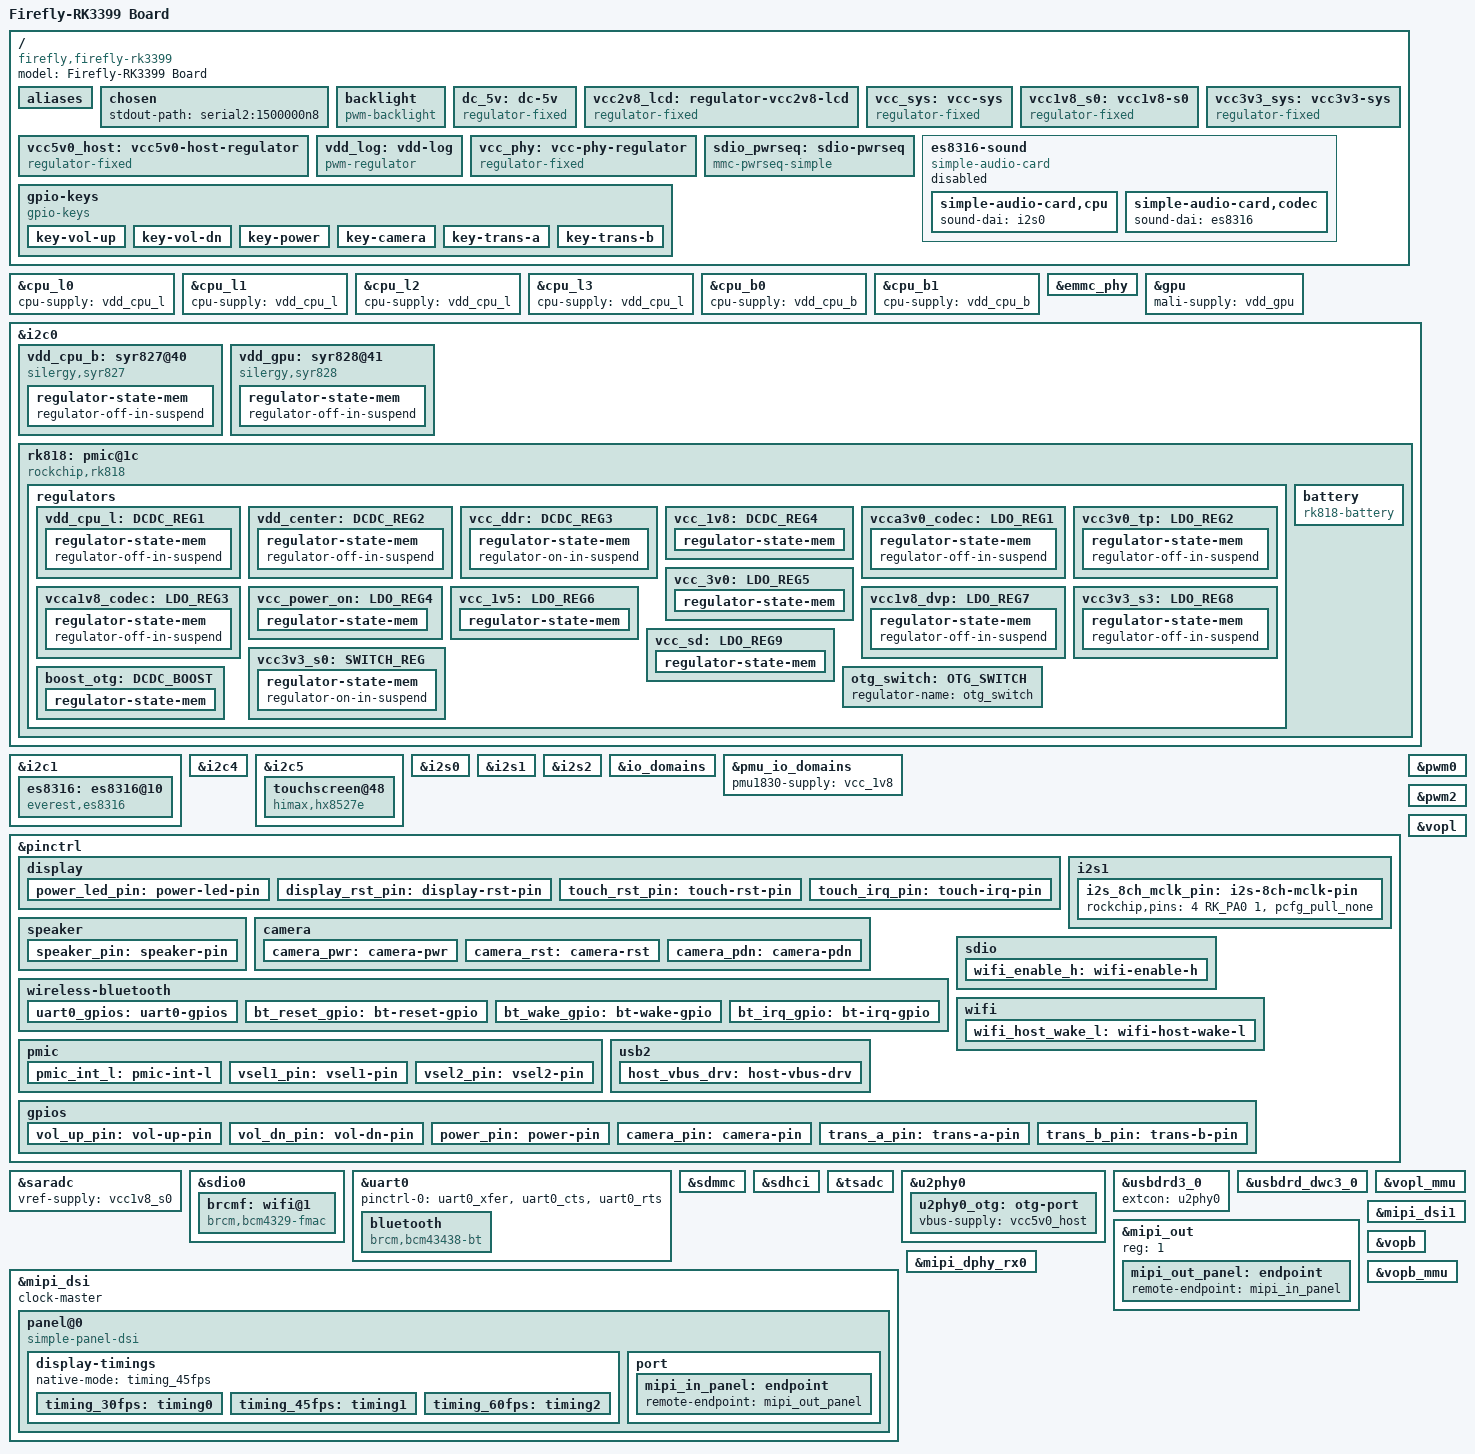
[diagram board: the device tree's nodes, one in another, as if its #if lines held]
// SPDX-License-Identifier: (GPL-2.0+ OR MIT)
/*
 * Copyright (c) 2017 Fuzhou Rockchip Electronics Co., Ltd.
 */

/dts-v1/;
#include <dt-bindings/input/linux-event-codes.h>
#include <dt-bindings/interrupt-controller/irq.h>
#include <dt-bindings/pwm/pwm.h>
#include <dt-bindings/usb/pd.h>
#include "rk3399.dtsi"

#define BLUETOOTH_ON  1
#define GPU_STRATEGY  0 /*1:Panfrost GPU  0:Midgard GPU*/
#define CAMERA_ONLINE 0
#define MAINLINE_LINUX	  1
/ {
	model = "Firefly-RK3399 Board";
	compatible = "firefly,firefly-rk3399", "rockchip,rk3399";

	aliases {
		mmc2 = &sdio0;
		mmc1 = &sdmmc;
		mmc0 = &sdhci;
	};

	chosen {
		stdout-path = "serial2:1500000n8";
	};

	//DONE 
	backlight: backlight {
		compatible = "pwm-backlight";
		enable-gpios = <&gpio1 RK_PB5 GPIO_ACTIVE_HIGH>;
		pwms = <&pwm0 0 25000 0>;
		brightness-levels = <
			  0   1   2   3   4   5   6   7
			  8   9  10  11  12  13  14  15
			 16  17  18  19  20  21  22  23
			 24  25  26  27  28  29  30  31
			 32  33  34  35  36  37  38  39
			 40  41  42  43  44  45  46  47
			 48  49  50  51  52  53  54  55
			 56  57  58  59  60  61  62  63
			 64  65  66  67  68  69  70  71
			 72  73  74  75  76  77  78  79
			 80  81  82  83  84  85  86  87
			 88  89  90  91  92  93  94  95
			 96  97  98  99 100 101 102 103
			104 105 106 107 108 109 110 111
			112 113 114 115 116 117 118 119
			120 121 122 123 124 125 126 127
			128 129 130 131 132 133 134 135
			136 137 138 139 140 141 142 143
			144 145 146 147 148 149 150 151
			152 153 154 155 156 157 158 159
			160 161 162 163 164 165 166 167
			168 169 170 171 172 173 174 175
			176 177 178 179 180 181 182 183
			184 185 186 187 188 189 190 191
			192 193 194 195 196 197 198 199
			200 201 202 203 204 205 206 207
			208 209 210 211 212 213 214 215
			216 217 218 219 220 221 222 223
			224 225 226 227 228 229 230 231
			232 233 234 235 236 237 238 239
			240 241 242 243 244 245 246 247
			248 249 250 251 252 253 254 255>;
		default-brightness-level = <250>;
	};

	dc_5v: dc-5v {
		compatible = "regulator-fixed";
		regulator-name = "dc_5v";
		regulator-always-on;
		regulator-boot-on;
		regulator-min-microvolt = <5000000>;
		regulator-max-microvolt = <5000000>;
	};

    vcc2v8_lcd: regulator-vcc2v8-lcd {
        compatible = "regulator-fixed";
        regulator-name = "vcc2v8_lcd";
		regulator-always-on;
		regulator-boot-on;
        regulator-min-microvolt = <2800000>;
        regulator-max-microvolt = <2800000>;
        vin-supply = <&dc_5v>;
    };


	//DONE
	vcc_sys: vcc-sys {
		compatible = "regulator-fixed";
		regulator-name = "vcc_sys";
		regulator-min-microvolt = <5000000>;
		regulator-max-microvolt = <5000000>;
		regulator-always-on;
		vin-supply = <&dc_5v>;
	};

	vcc1v8_s0: vcc1v8-s0 {
		compatible = "regulator-fixed";
		regulator-name = "vcc1v8_s0";
		regulator-min-microvolt = <1800000>;
		regulator-max-microvolt = <1800000>;
		regulator-always-on;
	};

	//DONE
	vcc3v3_sys: vcc3v3-sys {
		compatible = "regulator-fixed";
		regulator-name = "vcc3v3_sys";
		regulator-min-microvolt = <3300000>;
		regulator-max-microvolt = <3300000>;
		regulator-always-on;
		regulator-boot-on;
		vin-supply = <&vcc_sys>;
	};

	//DONE
#if (BAT_ALWAYS_CHARGE == 0)
	vcc5v0_host: vcc5v0-host-regulator {
		compatible = "regulator-fixed";
		enable-active-high;
		gpio = <&gpio4 RK_PD1 GPIO_ACTIVE_HIGH>;
		pinctrl-names = "default";
		pinctrl-0 = <&host_vbus_drv>;
		regulator-name = "vcc5v0_host";
		regulator-always-on;
	};
#endif 

	//DONE
	vdd_log: vdd-log {
		compatible = "pwm-regulator";
		pwms = <&pwm2 0 25000 1>;
		pwm-supply = <&vcc_sys>;
		regulator-name = "vdd_log";
		regulator-min-microvolt = <750000>;
		regulator-max-microvolt = <1350000>;
		regulator-always-on;
		regulator-boot-on;
	};

	//DONE
	vcc_phy: vcc-phy-regulator {
		compatible = "regulator-fixed";
		regulator-name = "vcc_phy";
		regulator-always-on;
		regulator-boot-on;
	};


	//DONE
	sdio_pwrseq: sdio-pwrseq {
		compatible = "mmc-pwrseq-simple";
		clocks = <&rk818 1>;
		clock-names = "ext_clock";
		pinctrl-names = "default";
		pinctrl-0 = <&wifi_enable_h>;
		reset-gpios = <&gpio0 RK_PB2 GPIO_ACTIVE_LOW>;
	};

	//DONE 
	gpio-keys {
		compatible = "gpio-keys";
		#address-cells = <1>;
		#size-cells = <0>;
		autorepeat;
		pinctrl-names = "default";
		pinctrl-0 = <&vol_up_pin>,<&vol_dn_pin>,<&power_pin>,<&camera_pin>,<&trans_a_pin>,<&trans_b_pin>;

		key-vol-up {
			debounce-interval = <100>;
			gpios = <&gpio1 RK_PB2 GPIO_ACTIVE_LOW>;
			label = "GPIO Key V+";
			linux,code = <KEY_VOLUMEUP>;
		};

		key-vol-dn {
			debounce-interval = <100>;
			gpios = <&gpio1 RK_PB0 GPIO_ACTIVE_LOW>;
			label = "GPIO Key V-";
			linux,code = <KEY_VOLUMEDOWN>;
		};

		key-power {
			debounce-interval = <100>;
			gpios = <&gpio0 RK_PA5 GPIO_ACTIVE_LOW>;
			label = "GPIO Key Power";
			linux,code = <KEY_POWER>;
		};

		key-camera {
			debounce-interval = <100>;
			gpios = <&gpio1 RK_PA1 GPIO_ACTIVE_LOW>;
			label = "GPIO key camera";
			linux,code = <KEY_ENTER>;
		};

		key-trans-a {
			debounce-interval = <100>;
			gpios = <&gpio1 RK_PC7 GPIO_ACTIVE_LOW>;
			label = "GPIO key trans a";
			linux,code = <KEY_UP>;
		};

		key-trans-b {
			debounce-interval = <100>;
			gpios = <&gpio1 RK_PC2 GPIO_ACTIVE_LOW>;
			label = "GPIO Key trans b";
			linux,code = <KEY_DOWN>;
		};
	};

	//DONE
	es8316-sound {
		compatible = "simple-audio-card";
		simple-audio-card,format = "i2s";
		simple-audio-card,name = "rockchip,es8316-codec";
		simple-audio-card,mclk-fs = <256>;

		status = "disabled";

		simple-audio-card,widgets =
			"Microphone", "Mic1 Jack",
			"Microphone", "Mic2 Jack",
			"Headphone", "Headphone Jack";

		simple-audio-card,routing =
			"Mic1 Jack", "Mic Bias",
			"MIC1", "Mic1 Jack",
			"Mic2 Jack", "Mic Bias",
			"MIC2", "Mic2 Jack",
			"Headphone Jack", "HPOL",
			"Headphone Jack", "HPOR";

		simple-audio-card,cpu {
			sound-dai = <&i2s0>;
		};

		simple-audio-card,codec {
			sound-dai = <&es8316>;
		};
	};
};

&cpu_l0 {
	cpu-supply = <&vdd_cpu_l>;
};

&cpu_l1 {
	cpu-supply = <&vdd_cpu_l>;
};

&cpu_l2 {
	cpu-supply = <&vdd_cpu_l>;
};

&cpu_l3 {
	cpu-supply = <&vdd_cpu_l>;
};

&cpu_b0 {
	cpu-supply = <&vdd_cpu_b>;
};

&cpu_b1 {
	cpu-supply = <&vdd_cpu_b>;
};

&emmc_phy {
	status = "okay";
};


&gpu {
#if GPU_STRATEGY
	compatible = "rockchip,rk3399-mali", "arm,mali-t860";
#endif 
	mali-supply = <&vdd_gpu>;
	status = "okay";
};


&i2c0 {
	status = "okay";
	i2c-scl-rising-time-ns = <180>;
	i2c-scl-falling-time-ns = <30>;
	clock-frequency = <400000>;

	//DONE
	vdd_cpu_b: syr827@40 {
		compatible = "silergy,syr827";
		reg = <0x40>;
		regulator-compatible = "fan53555-reg";
		pinctrl-0 = <&vsel1_pin>;
		vsel-gpios = <&gpio1 RK_PC1 GPIO_ACTIVE_HIGH>;
		regulator-name = "vdd_cpu_b";
		regulator-min-microvolt = <712500>;
		regulator-max-microvolt = <1500000>;
		regulator-ramp-delay = <1000>;
		fcs,suspend-voltage-selector = <1>;
		regulator-always-on;
		regulator-boot-on;
		vin-supply = <&vcc_sys>;
		regulator-state-mem {
			regulator-off-in-suspend;
		};
	};


	//DONE
	vdd_gpu: syr828@41 {
		compatible = "silergy,syr828";
		reg = <0x41>;
		regulator-compatible = "fan53555-reg";
		pinctrl-0 = <&vsel2_pin>;
		vsel-gpios = <&gpio1 RK_PB6 GPIO_ACTIVE_HIGH>;
		regulator-name = "vdd_gpu";
		regulator-min-microvolt = <712500>;
		regulator-max-microvolt = <1500000>;
		regulator-ramp-delay = <1000>;
		fcs,suspend-voltage-selector = <1>;
		regulator-always-on;
		regulator-boot-on;
		vin-supply = <&vcc_sys>;
		regulator-initial-mode = <1>;
		regulator-state-mem {
			regulator-off-in-suspend;
		};
	};

	//DONE
	rk818: pmic@1c {
		compatible = "rockchip,rk818";
		status = "okay";
		reg = <0x1c>;
		clock-output-names = "rk818-clkout1", "wifibt_32kin";
		interrupt-parent = <&gpio1>;
		interrupts = <21 IRQ_TYPE_LEVEL_LOW>;
		pinctrl-names = "default";
		pinctrl-0 = <&pmic_int_l>;
		rockchip,system-power-controller;
		
#if (BAT_ALWAYS_CHARGE == 0)
	rk818,support_dc_chg = <1>;/*1: dc chg; 0:usb chg*/
#else
	rk818,support_dc_chg = <0>;/*1: dc chg; 0:usb chg*/
#endif 
		extcon = <&u2phy0>;
		wakeup-source;
		#clock-cells = <1>;

		vcc1-supply = <&vcc_sys>;
		vcc2-supply = <&vcc_sys>;
		vcc3-supply = <&vcc_sys>;
		vcc4-supply = <&vcc_sys>;
		vcc6-supply = <&vcc_sys>;
		vcc7-supply = <&vcc3v3_sys>;
		vcc8-supply = <&vcc_sys>;
		vcc9-supply = <&vcc3v3_sys>;

		regulators {
			vdd_cpu_l: DCDC_REG1 {
				regulator-name = "vdd_cpu_l";
				regulator-always-on;
				regulator-boot-on;
				regulator-min-microvolt = <750000>;
				regulator-max-microvolt = <1350000>;
				regulator-ramp-delay = <6001>;
				regulator-state-mem {
					regulator-off-in-suspend;
				};
			};

			vdd_center: DCDC_REG2 {
				regulator-name = "vdd_center";
				regulator-always-on;
				regulator-boot-on;
				regulator-min-microvolt = <800000>;
				regulator-max-microvolt = <1350000>;
				regulator-ramp-delay = <6001>;
				regulator-state-mem {
					regulator-off-in-suspend;
				};
			};

			vcc_ddr: DCDC_REG3 {
				regulator-name = "vcc_ddr";
				regulator-always-on;
				regulator-boot-on;
				regulator-state-mem {
					regulator-on-in-suspend;
				};
			};

			vcc_1v8: DCDC_REG4 {
				regulator-name = "vcc_1v8";
				regulator-always-on;
				regulator-boot-on;
				regulator-min-microvolt = <1800000>;
				regulator-max-microvolt = <1800000>;
				regulator-state-mem {
					regulator-on-in-suspend;
					regulator-suspend-microvolt = <1800000>;
				};
			};

			vcca3v0_codec: LDO_REG1 {
				regulator-always-on;
				regulator-boot-on;
				regulator-min-microvolt = <3000000>;
				regulator-max-microvolt = <3000000>;
				regulator-name = "vcca3v0_codec";
				regulator-state-mem {
					regulator-off-in-suspend;
				};
			};

			vcc3v0_tp: LDO_REG2 {
				regulator-always-on;
				regulator-boot-on;
				regulator-min-microvolt = <3000000>;
				regulator-max-microvolt = <3000000>;
				regulator-name = "vcc3v0_tp";
				regulator-state-mem {
					regulator-off-in-suspend;
				};
			};

			vcca1v8_codec: LDO_REG3 {
				regulator-always-on;
				regulator-boot-on;
				regulator-min-microvolt = <1800000>;
				regulator-max-microvolt = <1800000>;
				regulator-name = "vcca1v8_codec";
				regulator-state-mem {
					regulator-off-in-suspend;
				};
			};

			vcc_power_on: LDO_REG4 {
				regulator-always-on;
				regulator-boot-on;
				regulator-min-microvolt = <3300000>;
				regulator-max-microvolt = <3300000>;
				regulator-name = "vcc_power_on";
				regulator-state-mem {
					regulator-on-in-suspend;
					regulator-suspend-microvolt = <3300000>;
				};
			};

			vcc_3v0: LDO_REG5 {
				regulator-always-on;
				regulator-boot-on;
				regulator-min-microvolt = <3000000>;
				regulator-max-microvolt = <3000000>;
				regulator-name = "vcc_3v0";
				regulator-state-mem {
					regulator-on-in-suspend;
					regulator-suspend-microvolt = <3000000>;
				};
			};

			vcc_1v5: LDO_REG6 {
				regulator-always-on;
				regulator-boot-on;
				regulator-min-microvolt = <1500000>;
				regulator-max-microvolt = <1500000>;
				regulator-name = "vcc_1v5";
				regulator-state-mem {
					regulator-on-in-suspend;
					regulator-suspend-microvolt = <1500000>;
				};
			};

			vcc1v8_dvp: LDO_REG7 {
				regulator-always-on;
				regulator-boot-on;
				regulator-min-microvolt = <1800000>;
				regulator-max-microvolt = <1800000>;
				regulator-name = "vcc1v8_dvp";
				regulator-state-mem {
					regulator-off-in-suspend;
				};
			};

			vcc3v3_s3: LDO_REG8 {
				regulator-always-on;
				regulator-boot-on;
				regulator-min-microvolt = <2600000>;
				regulator-max-microvolt = <3300000>;
				regulator-name = "vcc3v3_s3";
				regulator-state-mem {
					regulator-off-in-suspend;
				};
			};

			vcc_sd: LDO_REG9 {
				regulator-always-on;
				regulator-boot-on;
				regulator-min-microvolt = <1800000>;
				regulator-max-microvolt = <3300000>;
				regulator-name = "vcc_sd";
				regulator-state-mem {
					regulator-on-in-suspend;
					regulator-suspend-microvolt = <3300000>;
				};
			};

			vcc3v3_s0: SWITCH_REG {
				regulator-always-on;
				regulator-boot-on;
				regulator-name = "vcc3v3_s0";
				regulator-state-mem {
					regulator-on-in-suspend;
				};
			};

			boost_otg: DCDC_BOOST {
				regulator-name = "boost_otg";
				regulator-always-on;
				regulator-boot-on;
				regulator-min-microvolt = <5000000>;
				regulator-max-microvolt = <5000000>;
				regulator-state-mem {
					regulator-on-in-suspend;
					regulator-suspend-microvolt = <5000000>;
				};
			};

			otg_switch: OTG_SWITCH {
				regulator-name = "otg_switch";
			};
		};

		battery {
			compatible = "rk818-battery";
			ocv_table = <3400 3675 3689 3716 3740 3756 3768 3780
				3793 3807 3827 3853 3896 3937 3974 4007 4066
				4110 4161 4217 4308>;
			design_capacity = <1826>;
			design_qmax = <2009>;
			bat_res = <100>;
			max_input_current = <2000>;
			max_chrg_current = <1800>;
			max_chrg_voltage = <4350>;
			sleep_enter_current = <300>;
			sleep_exit_current = <300>;
			power_off_thresd = <3500>;
			zero_algorithm_vol = <3950>;
			fb_temperature = <105>;
			sample_res = <10>;
			max_soc_offset = <60>;
			energy_mode = <0>;
			monitor_sec = <5>;
			virtual_power = <0>;
			power_dc2otg = <0>;
		};
	};
};



&i2c1 {
	status = "okay";
	clock-frequency = <400000>;
	i2c-scl-rising-time-ns = <300>;
	i2c-scl-falling-time-ns = <30>;

	es8316: es8316@10 {
		#sound-dai-cells = <0>;
		compatible = "everest,es8316";
		reg = <0x10>;
		clocks = <&cru SCLK_I2S_8CH_OUT>;
		clock-names = "mclk";
		pinctrl-names = "default";
		pinctrl-0 = <&i2s_8ch_mclk_pin>, <&speaker_pin>;
		spk-con-gpio = <&gpio4 RK_PD4 GPIO_ACTIVE_HIGH>;
	};
};

&i2c4 {
	clock-frequency = <400000>;
	i2c-scl-rising-time-ns = <600>;
	i2c-scl-falling-time-ns = <40>;
	status = "okay";
};

&i2c5 {
	clock-frequency = <400000>;
	i2c-scl-rising-time-ns = <600>;
	i2c-scl-falling-time-ns = <40>;
	status = "okay";
	touchscreen@48 {
		reg = <0x48>;
		compatible = "himax,hx8527e", "himax,hx852es";
		interrupt-parent = <&gpio3>;
		interrupts = <RK_PB5 IRQ_TYPE_EDGE_FALLING>;
		
		pinctrl-names = "default";
		pinctrl-0 =   <&touch_rst_pin>,<&touch_irq_pin>;
		reset-gpios = <&gpio3 RK_PB4 GPIO_ACTIVE_LOW>;
		vcca-supply = <&vcc3v0_tp>;

		touchscreen-size-x = <480>;
		touchscreen-size-y = <800>;
	};
};

&i2s0 {
	rockchip,i2s-broken-burst-len;
	rockchip,playback-channels = <8>;
	rockchip,capture-channels = <8>;
	#sound-dai-cells = <0>;
	status = "okay";
};


&i2s1 {
	rockchip,playback-channels = <2>;
	rockchip,capture-channels = <2>;
	status = "okay";
};

&i2s2 {
	status = "okay";
};

&io_domains {
	status = "okay";
	bt656-supply = <&vcc1v8_dvp>;
	audio-supply = <&vcca1v8_codec>;
	sdmmc-supply = <&vcc_sd>;
	gpio1830-supply = <&vcc_3v0>;
};


&pmu_io_domains {
	status = "okay";
	pmu1830-supply = <&vcc_1v8>;
};


&pinctrl {
	display {
		power_led_pin: power-led-pin {
			rockchip,pins = <1 RK_PB5 RK_FUNC_GPIO &pcfg_pull_none>;
		};

		display_rst_pin: display-rst-pin {
			rockchip,pins = <3 RK_PA4 RK_FUNC_GPIO &pcfg_pull_none>;
		};

		touch_rst_pin: touch-rst-pin {
			rockchip,pins = <3 RK_PB4 RK_FUNC_GPIO &pcfg_pull_none>;
		};

		touch_irq_pin: touch-irq-pin {
			rockchip,pins = <3 RK_PB5 RK_FUNC_GPIO &pcfg_pull_up>;
		};
	};

	i2s1 {
		i2s_8ch_mclk_pin: i2s-8ch-mclk-pin {
			rockchip,pins = <4 RK_PA0 1 &pcfg_pull_none>;
		};
	};

	speaker {
		speaker_pin: speaker-pin {
			rockchip,pins = <4 RK_PD4 RK_FUNC_GPIO &pcfg_pull_up>;
		};
	};

	camera {
		camera_pwr: camera-pwr {
			rockchip,pins = <1 RK_PA2 RK_FUNC_GPIO &pcfg_pull_up>;
		};

		camera_rst: camera-rst {
			rockchip,pins = <2 RK_PD3 RK_FUNC_GPIO &pcfg_pull_up>;
		};

		camera_pdn: camera-pdn {
			rockchip,pins = <2 RK_PD4 RK_FUNC_GPIO &pcfg_pull_up>;
		};
	};

	wireless-bluetooth {
		uart0_gpios: uart0-gpios {
			rockchip,pins = <2 RK_PC3 RK_FUNC_GPIO &pcfg_pull_none>;
		};

		bt_reset_gpio: bt-reset-gpio {
			rockchip,pins = <0 RK_PB1 RK_FUNC_GPIO &pcfg_pull_none>;
		};

		bt_wake_gpio: bt-wake-gpio {
			rockchip,pins = <2 RK_PD2 RK_FUNC_GPIO &pcfg_pull_none>;
		};

		bt_irq_gpio: bt-irq-gpio {
			rockchip,pins = <0 RK_PA4 RK_FUNC_GPIO &pcfg_pull_down>;
		};
	};


	//DONE
	pmic {
		pmic_int_l: pmic-int-l {
			rockchip,pins = <1 RK_PC5 RK_FUNC_GPIO &pcfg_pull_up>;
		};

		vsel1_pin: vsel1-pin {
			rockchip,pins =<1 RK_PC1 RK_FUNC_GPIO &pcfg_pull_down>;
		};

		vsel2_pin: vsel2-pin {
			rockchip,pins =<1 RK_PB6 RK_FUNC_GPIO &pcfg_pull_down>;
		};
	};

	//DONE
	sdio {
		wifi_enable_h: wifi-enable-h {
			rockchip,pins = <0 RK_PB2 RK_FUNC_GPIO &pcfg_pull_none>;
		};
	};

	//DONE
	wifi {
		wifi_host_wake_l: wifi-host-wake-l {
			rockchip,pins = <0 RK_PA3 RK_FUNC_GPIO &pcfg_pull_none>;
		};
	};

	//DONE
	usb2 {
		host_vbus_drv: host-vbus-drv {
			rockchip,pins =<4 RK_PD1 RK_FUNC_GPIO &pcfg_pull_none>;
		};
	};

	//DONE
	gpios {
		vol_up_pin: vol-up-pin {
			rockchip,pins =<1 RK_PB2 RK_FUNC_GPIO &pcfg_pull_up>;
		};

		vol_dn_pin: vol-dn-pin {
			rockchip,pins =<1 RK_PB0 RK_FUNC_GPIO &pcfg_pull_up>;
		};

		power_pin: power-pin {
			rockchip,pins =<0 RK_PA5 RK_FUNC_GPIO &pcfg_pull_up>;
		};

		camera_pin: camera-pin {
			rockchip,pins =<1 RK_PA1 RK_FUNC_GPIO &pcfg_pull_up>;
		};

		trans_a_pin: trans-a-pin {
			rockchip,pins =<1 RK_PC7 RK_FUNC_GPIO &pcfg_pull_up>;
		};

		trans_b_pin: trans-b-pin {
			rockchip,pins =<1 RK_PC2 RK_FUNC_GPIO &pcfg_pull_up>;
		};
	};
};


&pwm0 {
	status = "okay";
};

&pwm2 {
	status = "okay";
};

&saradc {
	vref-supply = <&vcc1v8_s0>;
	status = "okay";
};


&sdio0 {
	supports-sdio;
	disable-wp;
	bus-width = <4>;
	clock-frequency = <15000000>;
	max-frequency = <15000000>;
	cap-sdio-irq;
	cap-sd-highspeed;
	keep-power-in-suspend;
	mmc-pwrseq = <&sdio_pwrseq>;
	non-removable;
	num-slots = <1>;
	pinctrl-names = "default";
	pinctrl-0 = <&sdio0_bus4 &sdio0_cmd &sdio0_clk>;
	sd-uhs-sdr104;
	status = "okay";

	#address-cells = <1>;
	#size-cells = <0>;
	brcmf: wifi@1 {
		reg = <1>;
		compatible = "brcm,bcm4329-fmac";
		interrupt-parent = <&gpio0>;
		interrupts = <RK_PA3 GPIO_ACTIVE_HIGH>;
		interrupt-names = "host-wake";
		brcm,drive-strength = <5>;
		pinctrl-names = "default";
		pinctrl-0 = <&wifi_host_wake_l>;
	};
};


&uart0 {
	pinctrl-names = "default";
	pinctrl-0 = <&uart0_xfer &uart0_cts &uart0_rts>;
	status = "okay";

	bluetooth {
		compatible = "brcm,bcm43438-bt";
	//	clocks = <&rk818 1>;
	//	clock-names = "ext_clock";
		shutdown-gpios = <&gpio0 RK_PB1 GPIO_ACTIVE_HIGH>;
		device-wakeup-gpios = <&gpio2 RK_PD2 GPIO_ACTIVE_HIGH>;
		host-wakeup-gpios = <&gpio0 RK_PA4 GPIO_ACTIVE_HIGH>;
		
		max-speed = <1500000>;
		pinctrl-names = "default";
		pinctrl-0 = <&bt_reset_gpio>,<&bt_wake_gpio>, <&bt_irq_gpio>;
		vbat-supply = <&vcc3v3_sys>;
		vddio-supply = <&vcc_1v8>;
	};
};


&sdmmc {
	clock-frequency = <150000000>;
	max-frequency = <150000000>;
	bus-width = <4>;
	cap-mmc-highspeed;
	cap-sd-highspeed;
	disable-wp;
	vqmmc-supply = <&vcc_sd>;
	pinctrl-names = "default";
	pinctrl-0 = <&sdmmc_clk &sdmmc_cmd &sdmmc_cd &sdmmc_bus4>;
	card-detect-delay = <800>;
	status = "okay";
};



&sdhci {
	bus-width = <8>;
	mmc-hs400-1_8v;
	mmc-hs400-enhanced-strobe;
	non-removable;
	status = "okay";
};


&tsadc {
	/* tshut mode 0:CRU 1:GPIO */
	rockchip,hw-tshut-mode = <1>;
	/* tshut polarity 0:LOW 1:HIGH */
	rockchip,hw-tshut-polarity = <1>;
	rockchip,hw-tshut-temp = <110000>;
	status = "okay";
};



&u2phy0 {
	status = "okay";
	u2phy0_otg: otg-port {
#if BAT_ALWAYS_CHARGE == 0
		vbus-supply = <&vcc5v0_host>;
#endif 
		status = "okay";
	};
};
&usbdrd3_0 {
	extcon = <&u2phy0>;
	status = "okay";
};

&usbdrd_dwc3_0 {
	status = "okay";
	maximum-speed = "high-speed";
	phys = <&u2phy0_otg>;
    phy-names = "usb2-phy";
	dr_mode = "peripheral";
	usb-role-switch;
};

#if 0
&rng {
	status = "okay";
};
#endif 

&vopl {
	status = "okay";
};

&vopl_mmu {
	status = "okay";
};


&mipi_dsi {
	clock-master;
	#address-cells = <1>;
	#size-cells = <0>;
	status = "okay";

	panel@0 {
		status = "okay";
		reg = <0>;
		backlight = <&backlight>;
		compatible = "simple-panel-dsi";
		power-supply = <&vcc2v8_lcd>;
		pinctrl-names = "default";
		pinctrl-0 = <&display_rst_pin>;
		reset-gpios = <&gpio3 RK_PA4 GPIO_ACTIVE_LOW>;

		prepare-delay-ms = <120>;
		reset-delay-ms = <120>;
		init-delay-ms = <120>;
		enable-delay-ms = <120>;
		disable-delay-ms = <120>;
		unprepare-delay-ms = <120>;

		dsi,flags = <3>;
		dsi,format = <0>;
		dsi,lanes  = <2>;

		width-mm = <68>;
		height-mm = <121>;
		bpc = <8>;

		panel-init-sequence = [
			39 00 04 b9 ff 83 79 
			39 00 11 b1 44 18 18 31 51 50 d0 d8 58 80 38 38 f8 33 32 22 
			39 00 0a b2 80 3c 0a 03 70 50 11 42 1d 
			39 00 0b b4 02 7c 02 7c 02 7c 22 86 23 86 
			39 00 05 c7 00 00 00 c0 
			15 00 02 cc 02 
			15 00 02 d2 77 
			39 00 26 d3 00 07 00 00 00 08 08 32 10 01 00 01 03 72 03 72 00 08 00 08 33 33 05 05 37 05 05 37 08 00 00 00 0a 00 01 01 0f 
			39 00 23 d5 18 18 18 18 18 18 07 06 05 04 03 02 01 00 18 18 21 20 18 18 19 19 23 22 38 38 78 78 18 18 18 18 00 00 
			39 00 21 d6 18 18 18 18 18 18 00 01 02 03 04 05 06 07 18 18 22 23 19 19 18 18 20 21 38 38 38 38 18 18 18 18 
			39 00 2b e0 00 01 04 20 24 3f 11 33 09 0a 0c 17 0f 12 15 13 14 0a 15 16 18 00 01 04 20 24 3f 11 33 09 0b 0c 17 03 11 14 13 14 0a 15 16 18 
			39 00 03 b6 5e 5e 
			05 ff 01 11 
			05 96 01 29];

		panel-exit-sequence = [
			05 00 01 28
			05 78 01 10
		];

		display-timings {
			native-mode = <&timing_45fps>;
			timing_30fps: timing0 {
				clock-frequency = <12948000>;
				hactive = <480>;
				vactive = <800>;
				hback-porch = <20>;
				hfront-porch = <10>;
				vback-porch = <10>;
				vfront-porch = <10>;
				hsync-len = <10>;
				vsync-len = <10>;
				hsync-active = <0x0>;
				vsync-active = <0x0>;
				de-active = <0x00>;
				pixelclk-active = <0x00>;
			};

			timing_45fps: timing1 {
				clock-frequency = <19422000>;
				hactive = <480>;
				vactive = <800>;
				hback-porch = <20>;
				hfront-porch = <10>;
				vback-porch = <10>;
				vfront-porch = <10>;
				hsync-len = <10>;
				vsync-len = <10>;
				hsync-active = <0x0>;
				vsync-active = <0x0>;
				de-active = <0x00>;
				pixelclk-active = <0x00>;
			};

			timing_60fps: timing2 {
				clock-frequency = <25896000>;
				hactive = <480>;
				vactive = <800>;
				hback-porch = <20>;
				hfront-porch = <10>;
				vback-porch = <10>;
				vfront-porch = <10>;
				hsync-len = <10>;
				vsync-len = <10>;
				hsync-active = <0x0>;
				vsync-active = <0x0>;
				de-active = <0x00>;
				pixelclk-active = <0x00>;
			};
		};
		
		port {
			#address-cells = <1>;
			#size-cells = <0>;
			mipi_in_panel: endpoint {
				remote-endpoint = <&mipi_out_panel>;
			};
		};
	};
};

&mipi_out {
	reg = <1>;
	#address-cells = <1>;
	#size-cells = <0>;
	mipi_out_panel: endpoint {
		remote-endpoint = <&mipi_in_panel>;
	};
};

&mipi_dphy_rx0 {
	status = "okay";
};

&mipi_dsi1 {
	status = "okay";
};

&vopb {
	status = "okay";
};

&vopb_mmu {
	status = "okay";
};

&vopl {
	status = "okay";
};

&vopl_mmu {
	status = "okay";
};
